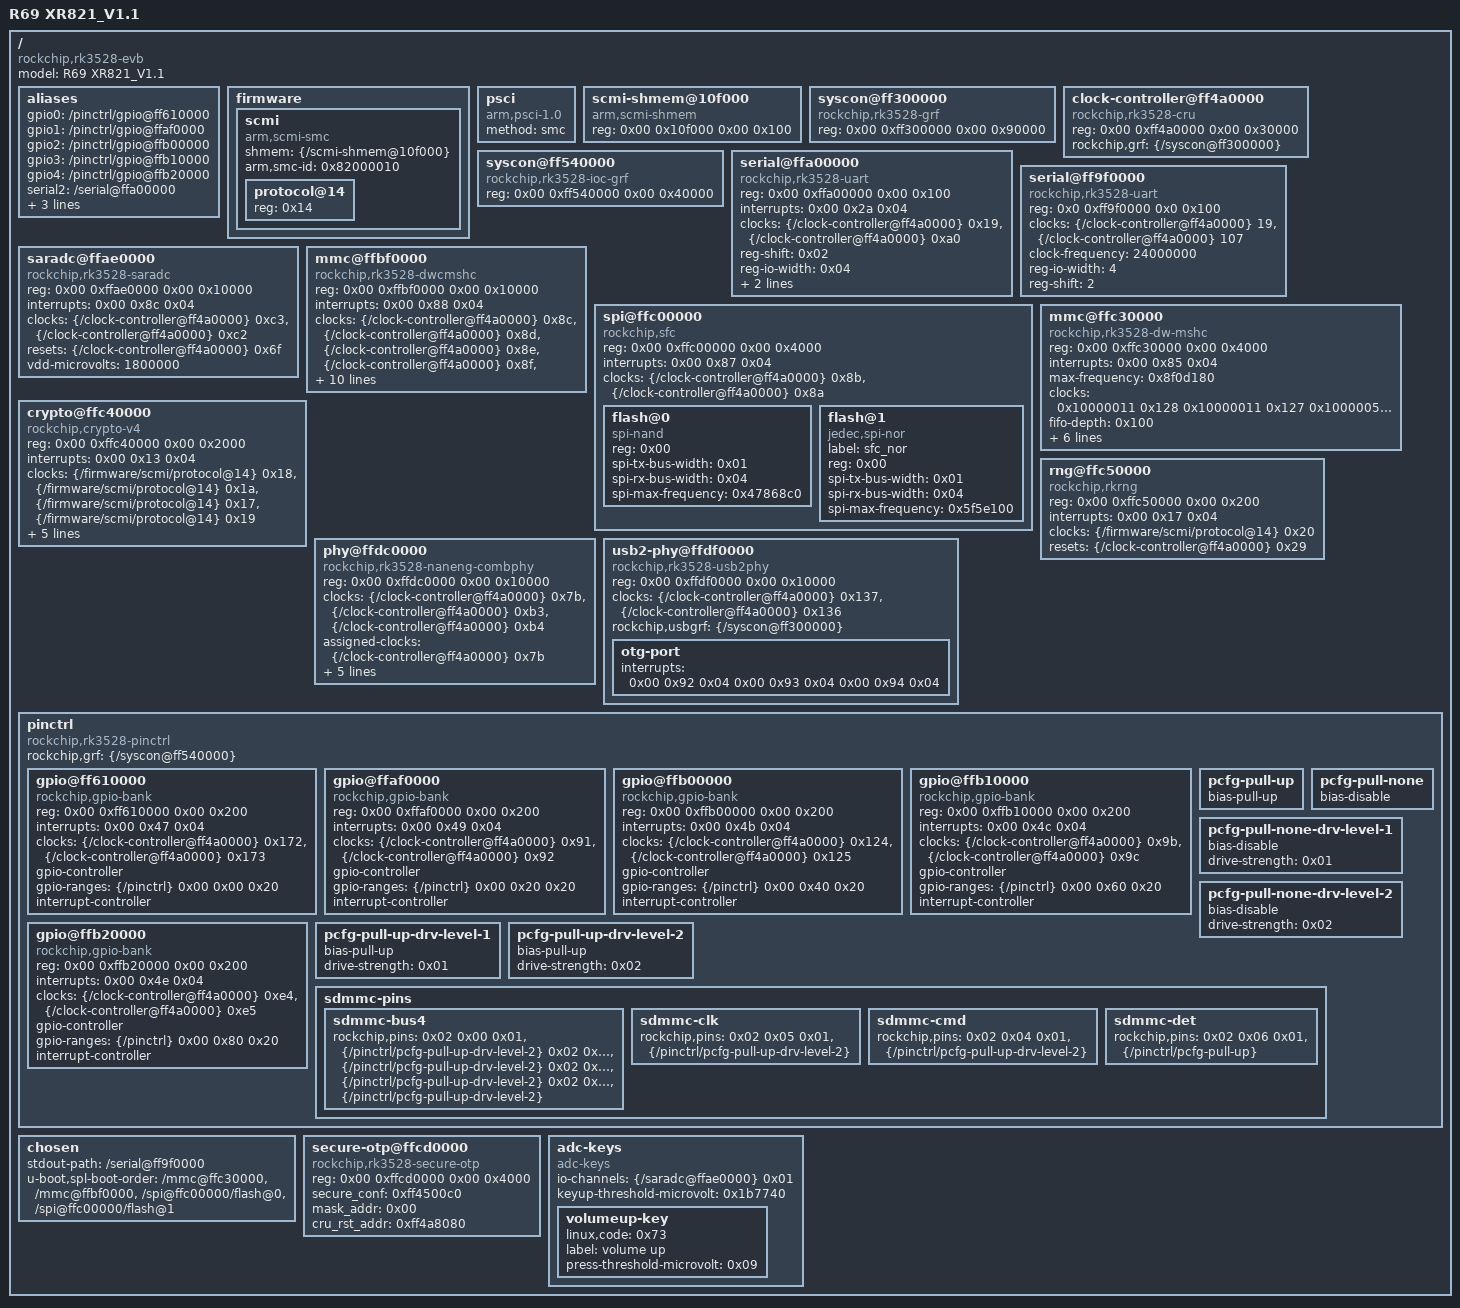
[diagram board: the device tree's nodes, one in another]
/dts-v1/;

/ {
	compatible = "rockchip,rk3528-evb", "rockchip,rk3528";
	#address-cells = <0x02>;
	#size-cells = <0x02>;
	/* the U-Boot banner's "Model:" line, so three near-identical boxes are
	 * distinguishable on a serial console; nothing else reads it */
	model = "R69 XR821_V1.1";

	aliases {
		gpio0 = "/pinctrl/gpio@ff610000";
		gpio1 = "/pinctrl/gpio@ffaf0000";
		gpio2 = "/pinctrl/gpio@ffb00000";
		gpio3 = "/pinctrl/gpio@ffb10000";
		gpio4 = "/pinctrl/gpio@ffb20000";
		serial2 = "/serial@ffa00000";
		spi2 = "/spi@ffc00000";
		mmc0 = "/mmc@ffbf0000";
		mmc1 = "/mmc@ffc30000";
	};

	firmware {
		bootph-pre-ram;

		scmi {
			compatible = "arm,scmi-smc";
			shmem = <&{/scmi-shmem@10f000}>;
			arm,smc-id = <0x82000010>;
			#address-cells = <0x01>;
			#size-cells = <0x00>;
			bootph-pre-ram;

			protocol@14 {
				reg = <0x14>;
				#clock-cells = <0x01>;
				bootph-pre-ram;
				phandle = <0x10000005>;
			};
		};
	};

	psci {
		compatible = "arm,psci-1.0";
		method = "smc";
		bootph-all;
		status = "okay";
	};

	scmi-shmem@10f000 {
		compatible = "arm,scmi-shmem";
		reg = <0x00 0x10f000 0x00 0x100>;
		bootph-pre-ram;
		phandle = <0x1000000f>;
	};

	syscon@ff300000 {
		compatible = "rockchip,rk3528-grf", "syscon", "simple-mfd";
		reg = <0x00 0xff300000 0x00 0x90000>;
		bootph-pre-ram;
		status = "okay";
		phandle = <0x1000000a>;
	};

	clock-controller@ff4a0000 {
		compatible = "rockchip,rk3528-cru";
		reg = <0x00 0xff4a0000 0x00 0x30000>;
		rockchip,grf = <&{/syscon@ff300000}>;
		#clock-cells = <0x01>;
		#reset-cells = <0x01>;
		bootph-pre-ram;
		status = "okay";
		phandle = <0x10000011>;
	};

	syscon@ff540000 {
		compatible = "rockchip,rk3528-ioc-grf", "syscon";
		reg = <0x00 0xff540000 0x00 0x40000>;
		bootph-pre-ram;
		status = "okay";
		phandle = <0x1000005c>;
	};

	serial@ffa00000 {
		compatible = "rockchip,rk3528-uart", "snps,dw-apb-uart";
		reg = <0x00 0xffa00000 0x00 0x100>;
		interrupts = <0x00 0x2a 0x04>;
		clocks = <&{/clock-controller@ff4a0000} 0x19 &{/clock-controller@ff4a0000} 0xa0>;
		reg-shift = <0x02>;
		reg-io-width = <0x04>;
		dmas = <0x1000002b 0x0d 0x1000002b 0x0c>;
		status = "okay";
		clock-frequency = <0x16e3600>;
		bootph-pre-ram;
	};

	/* Mainline picks its console from stdout-path, and the factory tree holds exactly one serial
	 * node - uart2 at ffa00000, status okay - so left alone the console binds there and the debug
	 * header falls silent once pre-relocation DEBUG_UART output stops. The header is uart0; the
	 * factory tree describes no uart0 because vendor U-Boot reaches it from code instead
	 * (boot log "PreSerial: 0, raw, 0xff9f0000"), which mainline has no equivalent of. */
	serial@ff9f0000 {
		compatible = "rockchip,rk3528-uart", "snps,dw-apb-uart";
		reg = <0x0 0xff9f0000 0x0 0x100>;
		clocks = <&{/clock-controller@ff4a0000} 19>,	/* SCLK_UART0 */
			 <&{/clock-controller@ff4a0000} 107>;	/* PCLK_UART0 */
		clock-names = "baudclk", "apb_pclk";
		clock-frequency = <24000000>;
		reg-io-width = <4>;
		reg-shift = <2>;
		bootph-all;
		status = "okay";
	};

	saradc@ffae0000 {
		compatible = "rockchip,rk3528-saradc";
		reg = <0x00 0xffae0000 0x00 0x10000>;
		interrupts = <0x00 0x8c 0x04>;
		#io-channel-cells = <0x01>;
		clocks = <&{/clock-controller@ff4a0000} 0xc3 &{/clock-controller@ff4a0000} 0xc2>;
		resets = <&{/clock-controller@ff4a0000} 0x6f>;
		reset-names = "saradc-apb";
		/* mainline's saradc driver fails probe with no vref-supply and no explicit reference;
		 * the vendor's defaulted, so the factory tree carries neither */
		vdd-microvolts = <1800000>;
		status = "okay";
		bootph-all;
		phandle = <0x10000062>;
	};

	mmc@ffbf0000 {
		compatible = "rockchip,rk3528-dwcmshc";
		reg = <0x00 0xffbf0000 0x00 0x10000>;
		interrupts = <0x00 0x88 0x04>;
		clocks = <&{/clock-controller@ff4a0000} 0x8c &{/clock-controller@ff4a0000} 0x8d &{/clock-controller@ff4a0000} 0x8e &{/clock-controller@ff4a0000} 0x8f &{/clock-controller@ff4a0000} 0x90>;
		resets = <&{/clock-controller@ff4a0000} 0x41 &{/clock-controller@ff4a0000} 0x42 &{/clock-controller@ff4a0000} 0x43 &{/clock-controller@ff4a0000} 0x44 &{/clock-controller@ff4a0000} 0x45>;
		reset-names = "core", "bus", "axi", "block", "timer";
		max-frequency = <0x2faf080>;
		status = "okay";
		bus-width = <0x08>;
		bootph-pre-ram;
		mmc-hs200-1_8v;
		fixed-emmc-driver-type = <0x01>;
	};

	spi@ffc00000 {
		compatible = "rockchip,sfc";
		reg = <0x00 0xffc00000 0x00 0x4000>;
		interrupts = <0x00 0x87 0x04>;
		clocks = <&{/clock-controller@ff4a0000} 0x8b &{/clock-controller@ff4a0000} 0x8a>;
		#address-cells = <0x01>;
		#size-cells = <0x00>;
		status = "okay";
		bootph-pre-ram;

		flash@0 {
			bootph-pre-ram;
			compatible = "spi-nand";
			reg = <0x00>;
			spi-tx-bus-width = <0x01>;
			spi-rx-bus-width = <0x04>;
			spi-max-frequency = <0x47868c0>;
		};

		flash@1 {
			bootph-pre-ram;
			compatible = "jedec,spi-nor";
			label = "sfc_nor";
			reg = <0x00>;
			spi-tx-bus-width = <0x01>;
			spi-rx-bus-width = <0x04>;
			spi-max-frequency = <0x5f5e100>;
		};
	};

	mmc@ffc30000 {
		compatible = "rockchip,rk3528-dw-mshc", "rockchip,rk3288-dw-mshc";
		reg = <0x00 0xffc30000 0x00 0x4000>;
		interrupts = <0x00 0x85 0x04>;
		max-frequency = <0x8f0d180>;
		clocks = <0x10000011 0x128 0x10000011 0x127 0x10000056 0x01 0x10000056 0x02>;
		fifo-depth = <0x100>;
		resets = <&{/clock-controller@ff4a0000} 0xbd>;
		reset-names = "reset";
		rockchip,use-v2-tuning;
		pinctrl-names = "default";
		pinctrl-0 = <&{/pinctrl/sdmmc-pins/sdmmc-clk} &{/pinctrl/sdmmc-pins/sdmmc-cmd} &{/pinctrl/sdmmc-pins/sdmmc-det} &{/pinctrl/sdmmc-pins/sdmmc-bus4}>;
		status = "okay";
		bootph-pre-ram;
	};

	crypto@ffc40000 {
		compatible = "rockchip,crypto-v4";
		reg = <0x00 0xffc40000 0x00 0x2000>;
		interrupts = <0x00 0x13 0x04>;
		clocks = <&{/firmware/scmi/protocol@14} 0x18 &{/firmware/scmi/protocol@14} 0x1a &{/firmware/scmi/protocol@14} 0x17 &{/firmware/scmi/protocol@14} 0x19>;
		assigned-clocks = <&{/firmware/scmi/protocol@14} 0x17 &{/firmware/scmi/protocol@14} 0x19>;
		assigned-clock-rates = <0x11e1a300 0x11e1a300>;
		resets = <&{/clock-controller@ff4a0000} 0xa>;
		reset-names = "crypto-rst";
		status = "okay";
		bootph-pre-ram;
	};

	rng@ffc50000 {
		compatible = "rockchip,rkrng";
		reg = <0x00 0xffc50000 0x00 0x200>;
		interrupts = <0x00 0x17 0x04>;
		clocks = <&{/firmware/scmi/protocol@14} 0x20>;
		resets = <&{/clock-controller@ff4a0000} 0x29>;
		reset-names = "reset";
		status = "okay";
		bootph-all;
	};

	phy@ffdc0000 {
		compatible = "rockchip,rk3528-naneng-combphy";
		reg = <0x00 0xffdc0000 0x00 0x10000>;
		#phy-cells = <0x01>;
		clocks = <&{/clock-controller@ff4a0000} 0x7b &{/clock-controller@ff4a0000} 0xb3 &{/clock-controller@ff4a0000} 0xb4>;
		assigned-clocks = <&{/clock-controller@ff4a0000} 0x7b>;
		assigned-clock-rates = <0x5f5e100>;
		resets = <&{/clock-controller@ff4a0000} 0x65 &{/clock-controller@ff4a0000} 0x63>;
		reset-names = "combphy-apb", "combphy";
		rockchip,pipe-grf = <&{/syscon@ff300000}>;
		rockchip,pipe-phy-grf = <&{/syscon@ff300000}>;
		status = "okay";
		bootph-all;
		phandle = <0x10000013>;
	};

	usb2-phy@ffdf0000 {
		compatible = "rockchip,rk3528-usb2phy";
		reg = <0x00 0xffdf0000 0x00 0x10000>;
		clocks = <&{/clock-controller@ff4a0000} 0x137 &{/clock-controller@ff4a0000} 0x136>;
		#clock-cells = <0x00>;
		rockchip,usbgrf = <&{/syscon@ff300000}>;
		status = "okay";
		bootph-all;
		phandle = <0x10000015>;

		otg-port {
			#phy-cells = <0x00>;
			interrupts = <0x00 0x92 0x04 0x00 0x93 0x04 0x00 0x94 0x04>;
			interrupt-names = "otg-bvalid", "otg-id", "linestate";
			status = "okay";
			bootph-all;
			phandle = <0x10000014>;
		};
	};

	pinctrl {
		compatible = "rockchip,rk3528-pinctrl";
		rockchip,grf = <&{/syscon@ff540000}>;
		#address-cells = <0x02>;
		#size-cells = <0x02>;
		ranges;
		bootph-pre-ram;
		status = "okay";
		phandle = <0x1000005d>;

		gpio@ff610000 {
			compatible = "rockchip,gpio-bank";
			reg = <0x00 0xff610000 0x00 0x200>;
			interrupts = <0x00 0x47 0x04>;
			clocks = <&{/clock-controller@ff4a0000} 0x172 &{/clock-controller@ff4a0000} 0x173>;
			gpio-controller;
			#gpio-cells = <0x02>;
			gpio-ranges = <&{/pinctrl} 0x00 0x00 0x20>;
			interrupt-controller;
			#interrupt-cells = <0x02>;
			bootph-pre-ram;
			phandle = <0x10000029>;
		};

		gpio@ffaf0000 {
			compatible = "rockchip,gpio-bank";
			reg = <0x00 0xffaf0000 0x00 0x200>;
			interrupts = <0x00 0x49 0x04>;
			clocks = <&{/clock-controller@ff4a0000} 0x91 &{/clock-controller@ff4a0000} 0x92>;
			gpio-controller;
			#gpio-cells = <0x02>;
			gpio-ranges = <&{/pinctrl} 0x00 0x20 0x20>;
			interrupt-controller;
			#interrupt-cells = <0x02>;
			bootph-pre-ram;
		};

		gpio@ffb00000 {
			compatible = "rockchip,gpio-bank";
			reg = <0x00 0xffb00000 0x00 0x200>;
			interrupts = <0x00 0x4b 0x04>;
			clocks = <&{/clock-controller@ff4a0000} 0x124 &{/clock-controller@ff4a0000} 0x125>;
			gpio-controller;
			#gpio-cells = <0x02>;
			gpio-ranges = <&{/pinctrl} 0x00 0x40 0x20>;
			interrupt-controller;
			#interrupt-cells = <0x02>;
			bootph-pre-ram;
		};

		gpio@ffb10000 {
			compatible = "rockchip,gpio-bank";
			reg = <0x00 0xffb10000 0x00 0x200>;
			interrupts = <0x00 0x4c 0x04>;
			clocks = <&{/clock-controller@ff4a0000} 0x9b &{/clock-controller@ff4a0000} 0x9c>;
			gpio-controller;
			#gpio-cells = <0x02>;
			gpio-ranges = <&{/pinctrl} 0x00 0x60 0x20>;
			interrupt-controller;
			#interrupt-cells = <0x02>;
			bootph-all;
		};

		gpio@ffb20000 {
			compatible = "rockchip,gpio-bank";
			reg = <0x00 0xffb20000 0x00 0x200>;
			interrupts = <0x00 0x4e 0x04>;
			clocks = <&{/clock-controller@ff4a0000} 0xe4 &{/clock-controller@ff4a0000} 0xe5>;
			gpio-controller;
			#gpio-cells = <0x02>;
			gpio-ranges = <&{/pinctrl} 0x00 0x80 0x20>;
			interrupt-controller;
			#interrupt-cells = <0x02>;
			bootph-all;
			phandle = <0x10000063>;
		};

		pcfg-pull-up {
			bias-pull-up;
			bootph-pre-ram;
			phandle = <0x10000061>;
		};

		pcfg-pull-none {
			bias-disable;
			bootph-pre-ram;
			phandle = <0x1000005e>;
		};

		pcfg-pull-none-drv-level-1 {
			bias-disable;
			drive-strength = <0x01>;
			bootph-pre-ram;
		};

		pcfg-pull-none-drv-level-2 {
			bias-disable;
			drive-strength = <0x02>;
			bootph-pre-ram;
		};

		pcfg-pull-up-drv-level-1 {
			bias-pull-up;
			drive-strength = <0x01>;
			bootph-pre-ram;
		};

		pcfg-pull-up-drv-level-2 {
			bias-pull-up;
			drive-strength = <0x02>;
			bootph-pre-ram;
			phandle = <0x1000005f>;
		};

		sdmmc-pins {
			bootph-pre-ram;

			sdmmc-bus4 {
				rockchip,pins = <0x02 0x00 0x01 &{/pinctrl/pcfg-pull-up-drv-level-2} 0x02 0x01 0x01 &{/pinctrl/pcfg-pull-up-drv-level-2} 0x02 0x02 0x01 &{/pinctrl/pcfg-pull-up-drv-level-2} 0x02 0x03 0x01 &{/pinctrl/pcfg-pull-up-drv-level-2}>;
				bootph-pre-ram;
				phandle = <0x1000005a>;
			};

			sdmmc-clk {
				rockchip,pins = <0x02 0x05 0x01 &{/pinctrl/pcfg-pull-up-drv-level-2}>;
				bootph-pre-ram;
				phandle = <0x10000057>;
			};

			sdmmc-cmd {
				rockchip,pins = <0x02 0x04 0x01 &{/pinctrl/pcfg-pull-up-drv-level-2}>;
				bootph-pre-ram;
				phandle = <0x10000058>;
			};

			sdmmc-det {
				rockchip,pins = <0x02 0x06 0x01 &{/pinctrl/pcfg-pull-up}>;
				bootph-pre-ram;
				phandle = <0x10000059>;
			};
		};
	};

	chosen {
		stdout-path = "/serial@ff9f0000";
		u-boot,spl-boot-order = "/mmc@ffc30000", "/mmc@ffbf0000", "/spi@ffc00000/flash@0", "/spi@ffc00000/flash@1";
	};

	secure-otp@ffcd0000 {
		compatible = "rockchip,rk3528-secure-otp";
		reg = <0x00 0xffcd0000 0x00 0x4000>;
		secure_conf = <0xff4500c0>;
		mask_addr = <0x00>;
		cru_rst_addr = <0xff4a8080>;
		bootph-pre-ram;
		status = "okay";
	};

	adc-keys {
		compatible = "adc-keys";
		io-channels = <&{/saradc@ffae0000} 0x01>;
		io-channel-names = "buttons";
		keyup-threshold-microvolt = <0x1b7740>;
		bootph-all;
		status = "okay";

		volumeup-key {
			bootph-all;
			linux,code = <0x73>;
			label = "volume up";
			press-threshold-microvolt = <0x09>;
		};
	};
};
